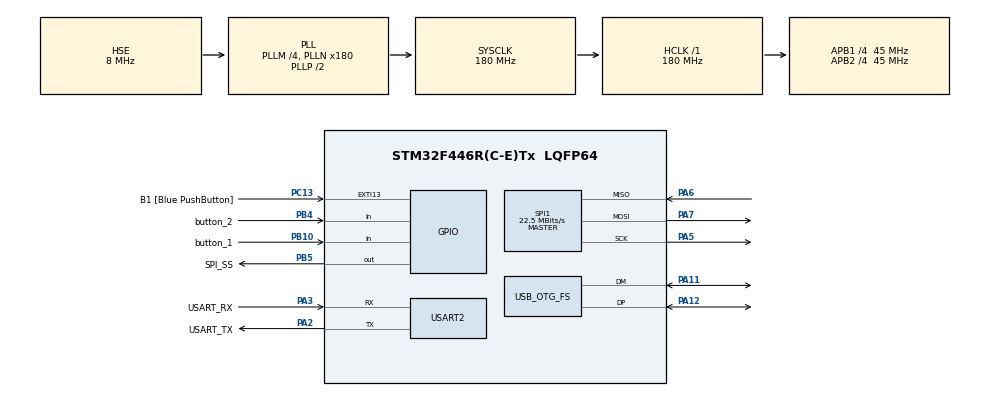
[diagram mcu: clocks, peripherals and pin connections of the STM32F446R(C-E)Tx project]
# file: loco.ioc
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FREERTOS.Tasks01=defaultTask,0,128,StartDefaultTask,Default,NULL
FREERTOS.configUSE_ALTERNATIVE_API=0
Mcu.Family=STM32F4
Mcu.Name=STM32F446R(C-E)Tx
Mcu.Package=LQFP64
NVIC.OTG_FS_IRQn=true\:5\:0\:false\:false\:true\:true
NVIC.PriorityGroup=NVIC_PRIORITYGROUP_4
NVIC.TIM1_UP_TIM10_IRQn=true\:5\:0\:false\:false\:true\:true
NVIC.TIM4_IRQn=true\:0\:0\:false\:false\:true\:false
NVIC.TimeBase=TIM4_IRQn
NVIC.TimeBaseIP=TIM4
PA11.Mode=Device_Only
PA11.Signal=USB_OTG_FS_DM
PA12.Mode=Device_Only
PA12.Signal=USB_OTG_FS_DP
PA13.GPIO_Label=TMS
PA13.Mode=Serial_Wire
PA13.Signal=SYS_JTMS-SWDIO
PA14.GPIO_Label=TCK
PA14.Mode=Serial_Wire
PA14.Signal=SYS_JTCK-SWCLK
PA2.GPIO_Label=USART_TX
PA2.Mode=Asynchronous
PA2.Signal=USART2_TX
PA3.GPIO_Label=USART_RX
PA3.Mode=Asynchronous
PA3.Signal=USART2_RX
PA5.Mode=Full_Duplex_Master
PA5.Signal=SPI1_SCK
PA6.Mode=Full_Duplex_Master
PA6.Signal=SPI1_MISO
PA7.Mode=Full_Duplex_Master
PA7.Signal=SPI1_MOSI
PB10.GPIO_Label=button_1
PB10.Signal=GPIO_Input
PB3.GPIO_Label=SWO
PB3.Signal=SYS_JTDO-SWO
PB4.GPIO_Label=button_2
PB4.Signal=GPIO_Input
PB5.GPIO_Label=SPI_SS
PB5.Signal=GPIO_Output
PC12.Signal=SDIO_CK
PC13.GPIO_Label=B1 [Blue PushButton]
PC13.GPIO_ModeDefaultEXTI=GPIO_MODE_IT_FALLING
PC13.Signal=GPXTI13
PC8.Signal=SDIO_D0
PH0-OSC_IN.Mode=HSE-External-Oscillator
PH0-OSC_IN.Signal=RCC_OSC_IN
PH1-OSC_OUT.Mode=HSE-External-Oscillator
PH1-OSC_OUT.Signal=RCC_OSC_OUT
ProjectManager.HeapSize=0x400
ProjectManager.StackSize=0x800
ProjectManager.TargetToolchain=TrueSTUDIO
RCC.AHBCLKDivider=RCC_SYSCLK_DIV1
RCC.AHBFreq_Value=180000000
RCC.APB1CLKDivider=RCC_HCLK_DIV4
RCC.APB1Freq_Value=45000000
RCC.APB1TimFreq_Value=90000000
RCC.APB2CLKDivider=RCC_HCLK_DIV4
RCC.APB2Freq_Value=45000000
RCC.APB2TimFreq_Value=90000000
RCC.CECEnable=false
RCC.ClockTypeHCLK=RCC_CLOCKTYPE_HCLK
RCC.ClockTypePCLK1=RCC_CLOCKTYPE_PCLK1
RCC.ClockTypePCLK2=RCC_CLOCKTYPE_PCLK2
RCC.ClockTypeSysClk=RCC_CLOCKTYPE_SYSCLK
RCC.CortexFreq_Value=180000000
RCC.Cortex_Div=SYSTICK_CLKSOURCE_HCLK
RCC.EnableFMPI2C1=false
RCC.EnableHSE=true
RCC.EnableHSERTCDevisor=false
RCC.EnableI2S1=false
RCC.EnableI2S2=false
RCC.EnableLSE=false
RCC.EnableLSERTC=false
RCC.EnableSAIA=false
RCC.EnableSAIB=false
RCC.EnableSDIO=false
RCC.EnableSPDIF=false
RCC.EnableUSB=true
RCC.EnbaleCSS=false
RCC.ExtClockEnable=false
RCC.FLatency-AdvancedSettings=FLASH_LATENCY_5
RCC.HCLKFreq_Value=180000000
RCC.HSEState=RCC_HSE_ON
RCC.HSE_VALUE=8000000
RCC.HSIState=RCC_HSI_OFF
RCC.HSI_VALUE=16000000
RCC.IWDGEnable=false
RCC.LSE_VALUE=32768
RCC.LSIState=RCC_LSI_OFF
RCC.MCO1OutPutEnable=false
RCC.MCO2OutPutEnable=false
RCC.OscillatorTypeHSE=RCC_OSCILLATORTYPE_HSE
RCC.OscillatorTypeHSI=RCC_OSCILLATORTYPE_HSI
RCC.PLLI2SP=RCC_PLLI2SP_DIV2
RCC.PLLM=4
RCC.PLLN=180
RCC.PLLP=RCC_PLLP_DIV2
RCC.PLLQ=3
RCC.PLLSAIM=8
RCC.PLLSAIP=RCC_PLLSAIP_DIV4
RCC.PLLSource=RCC_PLLSOURCE_HSE
RCC.PLLSourceVirtual=RCC_PLLSOURCE_HSE
RCC.PLLState=RCC_PLL_ON
RCC.RCC_MCODiv1=RCC_MCODIV_1
RCC.RCC_MCODiv2=RCC_MCODIV_1
RCC.RCC_PERIPHCLK_CK48Var=RCC_PERIPHCLK_CLK48
RCC.RCC_PERIPHCLK_SDIOVar=RCC_PERIPHCLK_SDIO
RCC.RCC_RTC_Clock_Source=RCC_RTCCLKSOURCE_LSI
RCC.RCC_RTC_Clock_SourceVirtual=RCC_RTCCLKSOURCE_LSI
RCC.RCC_RTC_Clock_Source_FROM_HSE=RCC_RTCCLKSOURCE_HSE_DIV2
RCC.RTCEnable=false
RCC.SDIOCLockSelection=RCC_SDIOCLKSOURCE_SYSCLK
RCC.SYSCLKFreq_VALUE=180000000
RCC.SYSCLKSource=RCC_SYSCLKSOURCE_PLLCLK
RCC.USBCLockSelection=RCC_CLK48CLKSOURCE_PLLSAIP
RCC.USBFreq_Value=48000000
RCC.VCOOutputFreq_Value=360000000
SPI1.BaudRatePrescaler=SPI_BAUDRATEPRESCALER_2
SPI1.CRCPolynomial=10
SPI1.CalculateBaudRate=22.5 MBits/s
SPI1.Direction=SPI_DIRECTION_2LINES
SPI1.Mode=SPI_MODE_MASTER
SPI1.VirtualType=VM_MASTER
TIM10.Channel=TIM_CHANNEL_1
TIM10.DefaultOCFastMode=TIM_OCFAST_DISABLE
TIM10.Period=10000
TIM7.TIM_MasterSlaveMode=TIM_MASTERSLAVEMODE_DISABLE
USART2.HwFlowCtl-Asynchronous=UART_HWCONTROL_NONE
USART2.VirtualMode=VM_ASYNC
USB_DEVICE.CLASS_NAME_FS=MSC
USB_DEVICE.USBD_HandleTypeDef_FS=hUsbDevice_OTG_FS
USB_DEVICE.VirtualModeFS=Msc_FS
USB_OTG_FS.VirtualMode=Device_Only
USB_OTG_FS.dev_endpoints=6
USB_OTG_FS.phy_itface=PCD_PHY_EMBEDDED
VP_CRC_VS_CRC.Mode=CRC_Activate
VP_FREERTOS_VS_ENABLE.Mode=Enabled
VP_SYS_VS_tim4.Mode=TIM4
VP_TIM10_VS_ClockSourceINT.Mode=Enable_Timer
VP_TIM10_VS_no_output1.Mode=Output Compare1 No Output
VP_TIM7_VS_ClockSourceINT.Mode=Enable_Timer
VP_USB_DEVICE_VS_USB_DEVICE_MSC_FS.Mode=MSC_FS
VP_WWDG_VS_WWDG.Mode=WWDG_Activate
board=NUCLEO-F446RE

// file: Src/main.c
/**
  ******************************************************************************
  * File Name          : main.c
  * Description        : Main program body
  ******************************************************************************
  *
  * Copyright (c) 2017 STMicroelectronics International N.V.
  * All rights reserved.
  *
  * Redistribution and use in source and binary forms, with or without
  * modification, are permitted, provided that the following conditions are met:
  *
  * 1. Redistribution of source code must retain the above copyright notice,
  *    this list of conditions and the following disclaimer.
  * 2. Redistributions in binary form must reproduce the above copyright notice,
  *    this list of conditions and the following disclaimer in the documentation
  *    and/or other materials provided with the distribution.
  * 3. Neither the name of STMicroelectronics nor the names of other
  *    contributors to this software may be used to endorse or promote products
  *    derived from this software without specific written permission.
  * 4. This software, including modifications and/or derivative works of this
  *    software, must execute solely and exclusively on microcontroller or
  *    microprocessor devices manufactured by or for STMicroelectronics.
  * 5. Redistribution and use of this software other than as permitted under
  *    this license is void and will automatically terminate your rights under
  *    this license.
  *
  * THIS SOFTWARE IS PROVIDED BY STMICROELECTRONICS AND CONTRIBUTORS "AS IS"
  * AND ANY EXPRESS, IMPLIED OR STATUTORY WARRANTIES, INCLUDING, BUT NOT
  * LIMITED TO, THE IMPLIED WARRANTIES OF MERCHANTABILITY, FITNESS FOR A
  * PARTICULAR PURPOSE AND NON-INFRINGEMENT OF THIRD PARTY INTELLECTUAL PROPERTY
  * RIGHTS ARE DISCLAIMED TO THE FULLEST EXTENT PERMITTED BY LAW. IN NO EVENT
  * SHALL STMICROELECTRONICS OR CONTRIBUTORS BE LIABLE FOR ANY DIRECT, INDIRECT,
  * INCIDENTAL, SPECIAL, EXEMPLARY, OR CONSEQUENTIAL DAMAGES (INCLUDING, BUT NOT
  * LIMITED TO, PROCUREMENT OF SUBSTITUTE GOODS OR SERVICES; LOSS OF USE, DATA,
  * OR PROFITS; OR BUSINESS INTERRUPTION) HOWEVER CAUSED AND ON ANY THEORY OF
  * LIABILITY, WHETHER IN CONTRACT, STRICT LIABILITY, OR TORT (INCLUDING
  * NEGLIGENCE OR OTHERWISE) ARISING IN ANY WAY OUT OF THE USE OF THIS SOFTWARE,
  * EVEN IF ADVISED OF THE POSSIBILITY OF SUCH DAMAGE.
  *
  ******************************************************************************
  */
#include "main.h"
#include "stm32f4xx_hal.h"
//#include "stm32f446xx.h"
#include "cmsis_os.h"
#include "crc.h"
#include "spi.h"
#include "tim.h"
#include "usart.h"
#include "usb_device.h"
#include "wwdg.h"
#include "gpio.h"

/* USER CODE BEGIN PV */
/* Private variables ---------------------------------------------------------*/

/* USER CODE END PV */

void SystemClock_Config(void);
void Error_Handler(void);
void MX_FREERTOS_Init(void);

/* USER CODE BEGIN PFP */
/* Private function prototypes -----------------------------------------------*/
TaskHandle_t debug_task;
uint32_t i=0;
void exampleTask(void* args) {

	while(1){
		i++;
		vTaskDelay( 1000 );
	}
}
/* USER CODE END PFP */

int main(void)
{

  /* MCU Configuration----------------------------------------------------------*/

  /* Reset of all peripherals, Initializes the Flash interface and the Systick. */
  HAL_Init();

  /* Configure the system clock */
  SystemClock_Config();

  /* Initialize all configured peripherals */
  MX_GPIO_Init();
  MX_TIM10_Init();
  MX_USART2_UART_Init();
  //MX_WWDG_Init();
  MX_SPI1_Init();
  MX_CRC_Init();
  MX_TIM7_Init();

  /* Call init function for freertos objects (in freertos.c) */
  MX_FREERTOS_Init();

  xTaskCreate(	exampleTask,
  				"debug",
  				80,
  				NULL,
  				(UBaseType_t)1,
				&debug_task);

  /* Start scheduler */
  osKernelStart();

  /* We should never get here as control is now taken by the scheduler */

  /* Infinite loop */
  while (1)
  {

  }

}

/** System Clock Configuration
*/
void SystemClock_Config(void)
{

  RCC_OscInitTypeDef RCC_OscInitStruct;
  RCC_ClkInitTypeDef RCC_ClkInitStruct;
  RCC_PeriphCLKInitTypeDef PeriphClkInitStruct;

    /**Configure the main internal regulator output voltage
    */
  __HAL_RCC_PWR_CLK_ENABLE();

  __HAL_PWR_VOLTAGESCALING_CONFIG(PWR_REGULATOR_VOLTAGE_SCALE1);

    /**Initializes the CPU, AHB and APB busses clocks
    */
  RCC_OscInitStruct.OscillatorType = RCC_OSCILLATORTYPE_HSE;
  RCC_OscInitStruct.HSEState = RCC_HSE_ON;
  RCC_OscInitStruct.PLL.PLLState = RCC_PLL_ON;
  RCC_OscInitStruct.PLL.PLLSource = RCC_PLLSOURCE_HSE;
  RCC_OscInitStruct.PLL.PLLM = 4;
  RCC_OscInitStruct.PLL.PLLN = 180;
  RCC_OscInitStruct.PLL.PLLP = RCC_PLLP_DIV2;
  RCC_OscInitStruct.PLL.PLLQ = 3;
  RCC_OscInitStruct.PLL.PLLR = 2;
  if (HAL_RCC_OscConfig(&RCC_OscInitStruct) != HAL_OK)
  {
    Error_Handler();
  }

    /**Activate the Over-Drive mode
    */
  if (HAL_PWREx_EnableOverDrive() != HAL_OK)
  {
    Error_Handler();
  }

    /**Initializes the CPU, AHB and APB busses clocks
    */
  RCC_ClkInitStruct.ClockType = RCC_CLOCKTYPE_HCLK|RCC_CLOCKTYPE_SYSCLK
                              |RCC_CLOCKTYPE_PCLK1|RCC_CLOCKTYPE_PCLK2;
  RCC_ClkInitStruct.SYSCLKSource = RCC_SYSCLKSOURCE_PLLCLK;
  RCC_ClkInitStruct.AHBCLKDivider = RCC_SYSCLK_DIV1;
  RCC_ClkInitStruct.APB1CLKDivider = RCC_HCLK_DIV4;
  RCC_ClkInitStruct.APB2CLKDivider = RCC_HCLK_DIV4;

  if (HAL_RCC_ClockConfig(&RCC_ClkInitStruct, FLASH_LATENCY_5) != HAL_OK)
  {
    Error_Handler();
  }

  PeriphClkInitStruct.PeriphClockSelection = RCC_PERIPHCLK_SDIO|RCC_PERIPHCLK_CLK48;
  PeriphClkInitStruct.PLLSAI.PLLSAIM = 8;
  PeriphClkInitStruct.PLLSAI.PLLSAIN = 192;
  PeriphClkInitStruct.PLLSAI.PLLSAIQ = 2;
  PeriphClkInitStruct.PLLSAI.PLLSAIP = RCC_PLLSAIP_DIV4;
  PeriphClkInitStruct.PLLSAIDivQ = 1;
  PeriphClkInitStruct.Clk48ClockSelection = RCC_CLK48CLKSOURCE_PLLSAIP;
  if (HAL_RCCEx_PeriphCLKConfig(&PeriphClkInitStruct) != HAL_OK)
  {
    Error_Handler();
  }

    /**Configure the Systick interrupt time
    */
  HAL_SYSTICK_Config(HAL_RCC_GetHCLKFreq()/1000);

    /**Configure the Systick
    */
  HAL_SYSTICK_CLKSourceConfig(SYSTICK_CLKSOURCE_HCLK);

  /* SysTick_IRQn interrupt configuration */
  HAL_NVIC_SetPriority(SysTick_IRQn, 15, 0);
}

void HAL_TIM_PeriodElapsedCallback(TIM_HandleTypeDef *htim)
{
  if (htim->Instance == TIM4) {
    HAL_IncTick();
  }
}

void Error_Handler(void)
{
  while(1)
  {
  }
}

/************************ (C) COPYRIGHT STMicroelectronics *****END OF FILE****/

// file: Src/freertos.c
/**
  ******************************************************************************
  * File Name          : freertos.c
  * Description        : Code for freertos applications
  ******************************************************************************
  *
  * Copyright (c) 2017 STMicroelectronics International N.V.
  * All rights reserved.
  *
  * Redistribution and use in source and binary forms, with or without
  * modification, are permitted, provided that the following conditions are met:
  *
  * 1. Redistribution of source code must retain the above copyright notice,
  *    this list of conditions and the following disclaimer.
  * 2. Redistributions in binary form must reproduce the above copyright notice,
  *    this list of conditions and the following disclaimer in the documentation
  *    and/or other materials provided with the distribution.
  * 3. Neither the name of STMicroelectronics nor the names of other
  *    contributors to this software may be used to endorse or promote products
  *    derived from this software without specific written permission.
  * 4. This software, including modifications and/or derivative works of this
  *    software, must execute solely and exclusively on microcontroller or
  *    microprocessor devices manufactured by or for STMicroelectronics.
  * 5. Redistribution and use of this software other than as permitted under
  *    this license is void and will automatically terminate your rights under
  *    this license.
  *
  * THIS SOFTWARE IS PROVIDED BY STMICROELECTRONICS AND CONTRIBUTORS "AS IS"
  * AND ANY EXPRESS, IMPLIED OR STATUTORY WARRANTIES, INCLUDING, BUT NOT
  * LIMITED TO, THE IMPLIED WARRANTIES OF MERCHANTABILITY, FITNESS FOR A
  * PARTICULAR PURPOSE AND NON-INFRINGEMENT OF THIRD PARTY INTELLECTUAL PROPERTY
  * RIGHTS ARE DISCLAIMED TO THE FULLEST EXTENT PERMITTED BY LAW. IN NO EVENT
  * SHALL STMICROELECTRONICS OR CONTRIBUTORS BE LIABLE FOR ANY DIRECT, INDIRECT,
  * INCIDENTAL, SPECIAL, EXEMPLARY, OR CONSEQUENTIAL DAMAGES (INCLUDING, BUT NOT
  * LIMITED TO, PROCUREMENT OF SUBSTITUTE GOODS OR SERVICES; LOSS OF USE, DATA,
  * OR PROFITS; OR BUSINESS INTERRUPTION) HOWEVER CAUSED AND ON ANY THEORY OF
  * LIABILITY, WHETHER IN CONTRACT, STRICT LIABILITY, OR TORT (INCLUDING
  * NEGLIGENCE OR OTHERWISE) ARISING IN ANY WAY OUT OF THE USE OF THIS SOFTWARE,
  * EVEN IF ADVISED OF THE POSSIBILITY OF SUCH DAMAGE.
  *
  ******************************************************************************
  */

#include "FreeRTOS.h"
#include "task.h"
#include "cmsis_os.h"

osThreadId defaultTaskHandle;

void StartDefaultTask(void const * argument);

extern void MX_USB_DEVICE_Init(void);
void MX_FREERTOS_Init(void); /* (MISRA C 2004 rule 8.1) */

/* Hook prototypes */

/* Init FreeRTOS */

void MX_FREERTOS_Init(void) {

  /* Create the thread(s) */
  /* definition and creation of defaultTask */
  osThreadDef(defaultTask, StartDefaultTask, osPriorityNormal, 0, 128);
  defaultTaskHandle = osThreadCreate(osThread(defaultTask), NULL);

}

/* StartDefaultTask function */
void StartDefaultTask(void const * argument)
{
  /* init code for USB_DEVICE */
  MX_USB_DEVICE_Init();

  for(;;)
  {
    osDelay(1);
  }
}

/************************ (C) COPYRIGHT STMicroelectronics *****END OF FILE****/
